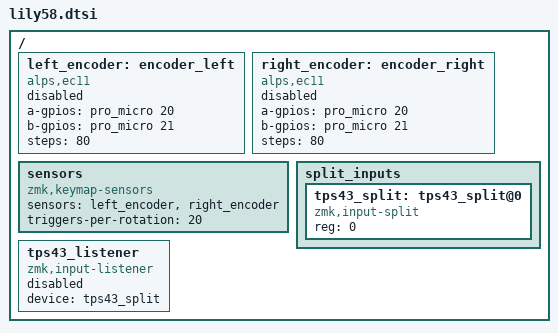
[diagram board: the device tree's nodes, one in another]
/ {
    left_encoder: encoder_left {
        compatible = "alps,ec11";
        a-gpios = <&pro_micro 20 (GPIO_ACTIVE_HIGH | GPIO_PULL_UP)>;
        b-gpios = <&pro_micro 21 (GPIO_ACTIVE_HIGH | GPIO_PULL_UP)>;
        steps = <80>;
        status = "disabled";
    };

    right_encoder: encoder_right {
        compatible = "alps,ec11";
        a-gpios = <&pro_micro 20 (GPIO_ACTIVE_HIGH | GPIO_PULL_UP)>;
        b-gpios = <&pro_micro 21 (GPIO_ACTIVE_HIGH | GPIO_PULL_UP)>;
        steps = <80>;
        status = "disabled";
    };

    sensors: sensors {
        compatible = "zmk,keymap-sensors";
        sensors = <&left_encoder &right_encoder>;
        triggers-per-rotation = <20>;
    };

    split_inputs {
        #address-cells = <1>;
        #size-cells = <0>;

        tps43_split: tps43_split@0 {
            compatible = "zmk,input-split";
            reg = <0>;
        };
    };

    tps43_listener: tps43_listener {
        compatible = "zmk,input-listener";
        status = "disabled";
        device = <&tps43_split>;
    };
};
